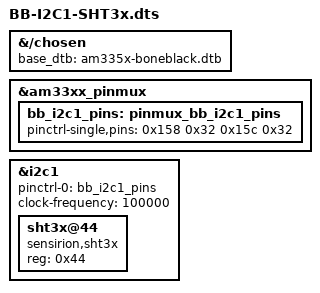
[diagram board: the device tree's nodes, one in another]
/dts-v1/;
/plugin/;

&{/chosen} {
    base_dtb = "am335x-boneblack.dtb";
};

&am33xx_pinmux {
    bb_i2c1_pins: pinmux_bb_i2c1_pins {
        pinctrl-single,pins = <
            0x158 0x32  /* P9_18: I2C1_SDA */
            0x15c 0x32  /* P9_17: I2C1_SCL */
        >;
    };
};

&i2c1 {
    #address-cells = <1>;
    #size-cells = <0>;
    status = "okay";
    pinctrl-names = "default";
    pinctrl-0 = <&bb_i2c1_pins>;
    clock-frequency = <100000>;

    sht3x@44 {
        compatible = "sensirion,sht3x";
        reg = <0x44>;
    };
};
